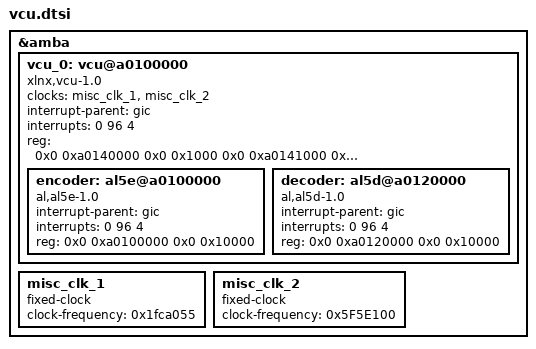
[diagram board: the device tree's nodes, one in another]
&amba {
	vcu_0: vcu@a0100000 {
		#address-cells = <2>;
		#size-cells = <2>;
		clock-names = "pll_ref", "aclk";
		clocks = <&misc_clk_1 &misc_clk_2>;
		compatible = "xlnx,vcu-1.0", "xlnx,vcu";
		interrupt-parent = <&gic>;
		interrupts = <0 96 4>;
		ranges ;
		reg = <0x0 0xa0140000 0x0 0x1000 0x0 0xa0141000 0x0 0x1000>;

		reg-names = "vcu_slcr", "logicore";

		encoder: al5e@a0100000 {
			compatible = "al,al5e-1.0", "al,al5e";
			interrupt-parent = <&gic>;
			interrupts = <0 96 4>;
			reg = <0x0 0xa0100000 0x0 0x10000>;
		};

		decoder: al5d@a0120000 {
			compatible = "al,al5d-1.0", "al,al5d";
			interrupt-parent = <&gic>;
			interrupts = <0 96 4>;
			reg = <0x0 0xa0120000 0x0 0x10000>;
		};
	};
	misc_clk_1:misc_clk_1 {
		#clock-cells = <0x0>;
		clock-frequency = <0x1fca055>;
		compatible = "fixed-clock";
	};

	misc_clk_2:misc_clk_2 {
		#clock-cells = <0x0>;
		clock-frequency = <0x5F5E100>;
		compatible = "fixed-clock";
	};
};

